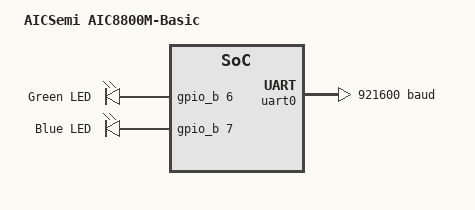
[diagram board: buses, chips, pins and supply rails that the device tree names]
/*
 * Copyright (c) 2022, Talpa Chen
 * SPDX-License-Identifier: Apache-2.0
 */

/dts-v1/;

#include <aicsemi/aic8800m.dtsi>
#include <zephyr/dt-bindings/gpio/gpio.h>
#include "aic8800m_basic-pinctrl.dtsi"

/ {
	model = "AICSemi AIC8800M-Basic";
	compatible = "aicsemi,aic8800m-basic";

	chosen {
		zephyr,sram = &sram0;
		zephyr,flash = &flash0;
		zephyr,console = &uart0;
		zephyr,shell-uart = &uart0;
	};

	leds {
		compatible = "gpio-leds";
		led0: led_green {
			gpios = <&gpio_b 6 GPIO_ACTIVE_HIGH>;
			label = "Green LED";
		};
		led1: led_blue {
			gpios = <&gpio_b 7 GPIO_ACTIVE_HIGH>;
			label = "Blue LED";
		};
	};

	aliases {
		led0 = &led0;
		led1 = &led1;
	};
};

&cpu0 {
	clock-frequency = <240000000>;
};

&uart0 {
	current-speed = <921600>;
	status = "okay";
	pinctrl-0 = <&uart0_default>;
	pinctrl-names = "default";
};

&gpio_a {
	status = "okay";
};

&gpio_a {
	status = "okay";
};
